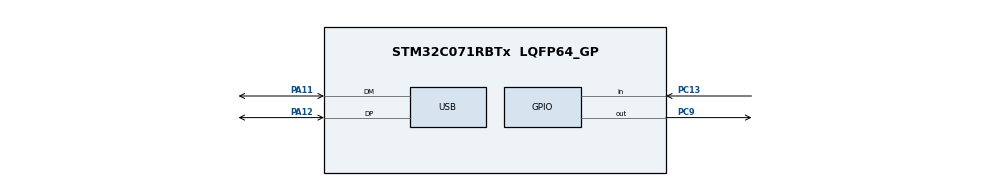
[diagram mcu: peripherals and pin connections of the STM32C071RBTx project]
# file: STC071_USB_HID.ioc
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Mcu.Family=STM32C0
Mcu.Name=STM32C071RBTx
Mcu.Package=LQFP64_GP
NUCLEO-C071RB.BUTTON=1
NUCLEO-C071RB.Bsp_Common_DEMO=true
NUCLEO-C071RB.LD1=true
NUCLEO-C071RB.LD2=true
NUCLEO-C071RB.VCP=true
NVIC.EXTI4_15_IRQn=true\:0\:0\:false\:false\:true\:false\:true\:true
NVIC.USB_DRD_FS_IRQn=true\:0\:0\:false\:false\:true\:true\:true\:true
PA11\ [PA9].Mode=Device
PA11\ [PA9].Signal=USB_DM
PA12\ [PA10].Mode=Device
PA12\ [PA10].Signal=USB_DP
PA13.Mode=Serial_Wire
PA13.Signal=DEBUG_SWDIO
PA14-BOOT0.Mode=Serial_Wire
PA14-BOOT0.Signal=DEBUG_SWCLK
PA2.Signal=USART2_TX
PA3.Signal=USART2_RX
PC13.Signal=GPIO_Input
PC9.Signal=GPIO_Output
PF0-OSC_IN(PF0).Mode=HSE-External-Oscillator
PF0-OSC_IN(PF0).Signal=RCC_OSC_IN
PF1-OSC_OUT(PF1).Mode=HSE-External-Oscillator
PF1-OSC_OUT(PF1).Signal=RCC_OSC_OUT
ProjectManager.HeapSize=0x1000
ProjectManager.StackSize=0x1000
ProjectManager.TargetToolchain=EWARM V9.30
RCC.ADCFreq_Value=48000000
RCC.AHBFreq_Value=48000000
RCC.CortexFreq_Value=48000000
RCC.EXTERNAL_CLOCK_VALUE=12288000
RCC.HCLKFreq_Value=48000000
RCC.HSE_VALUE=48000000
RCC.HSI48_VALUE=48000000
RCC.HSI_VALUE=48000000
RCC.LSE_VALUE=32768
RCC.SYSCLKFreq_VALUE=48000000
RCC.SYSCLKSource=RCC_SYSCLKSOURCE_HSE
USB.VirtualMode=Device_Only
USBX.BSP.number=1
USBX.Core_System=1
USBX.REG_USBX_DEVICE_CON_CK=0
USBX.USBD_COMPOSITE_USE_IAD=0
USBX.USBX_DEVICE_SYS_SIZE=5*1024
USBX.UX_DEVICE_APP_MEM_POOL_SIZE_STANDALONE=10*1024
USBX.UX_DEVICE_HID_CORE=1
USBX.UX_DEVICE_HID_MOUSE=1
USBX.UX_Device_Controller=1
USBX.UX_Device_CoreStack=1
USBX.UX_SLAVE_REQUEST_DATA_MAX_LENGTH=64
USBX0.BSP.STBoard=false
USBX0.BSP.api=Unknown
USBX0.BSP.instance=USB
USBX0.BSP.ip=USB
USBX0.BSP.mode=Device_Only
USBX0.BSP.name=USB_Device
USBX0.BSP.solution=USB
VP_NUCLEO-C071RB_VS_BSP_COMMON.Mode=COMMON
VP_USBX_Core_System.Mode=Core_System
VP_USBX_UX\ Device\ Controller_FS.Mode=UX_Device_Controller_FS
VP_USBX_UX\ Device\ CoreStack_FS.Mode=UX_Device_CoreStack_FS
VP_USBX_UX\ Device\ HID_CORE_FS.Mode=UX_Device_class_HID_CORE_FS
VP_USBX_UX\ Device\ HID_MOUSE_FS.Mode=UX_Device_class_HID_MOUSE_FS
board=NUCLEO-C071RB

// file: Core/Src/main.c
/* USER CODE BEGIN Header */
/**
  ******************************************************************************
  * @file           : main.c
  * @brief          : Main program body
  ******************************************************************************
  * @attention
  *
  * Copyright (c) 2026 STMicroelectronics.
  * All rights reserved.
  *
  * This software is licensed under terms that can be found in the LICENSE file
  * in the root directory of this software component.
  * If no LICENSE file comes with this software, it is provided AS-IS.
  *
  ******************************************************************************
  */
/* USER CODE END Header */
#include "main.h"
#include "usb.h"
#include "app_usbx_device.h"
#include "gpio.h"

COM_InitTypeDef BspCOMInit;
__IO uint32_t BspButtonState = BUTTON_RELEASED;

/* USER CODE BEGIN PV */

const char software_version[] = "V0.0.1";

/* USER CODE END PV */

void SystemClock_Config(void);

int main(void)
{

  /* MCU Configuration--------------------------------------------------------*/

  /* Reset of all peripherals, Initializes the Flash interface and the Systick. */
  HAL_Init();

  /* Configure the system clock */
  SystemClock_Config();

  /* Initialize all configured peripherals */
  MX_GPIO_Init();
  MX_USBX_Device_Init();

  /* Initialize leds */
  BSP_LED_Init(LED_GREEN);
  BSP_LED_Init(LED_BLUE);

  /* Initialize USER push-button, will be used to trigger an interrupt each time it's pressed.*/
  BSP_PB_Init(BUTTON_USER, BUTTON_MODE_EXTI);

  /* Initialize COM1 port (115200, 8 bits (7-bit data + 1 stop bit), no parity */
  BspCOMInit.BaudRate   = 115200;
  BspCOMInit.WordLength = COM_WORDLENGTH_8B;
  BspCOMInit.StopBits   = COM_STOPBITS_1;
  BspCOMInit.Parity     = COM_PARITY_NONE;
  BspCOMInit.HwFlowCtl  = COM_HWCONTROL_NONE;
  if (BSP_COM_Init(COM1, &BspCOMInit) != BSP_ERROR_NONE)
  {
    Error_Handler();
  }

  /* USER CODE BEGIN BSP */

  /* -- Sample board code to send message over COM1 port ---- */

  printf("%s\n\r", software_version);
  printf("USB HID MOUSE!\n\r");

  /* -- Sample board code to switch on leds ---- */
  BSP_LED_On(LED_GREEN);
  BSP_LED_On(LED_BLUE);

  /* USER CODE END BSP */

  /* Infinite loop */
  /* USER CODE BEGIN WHILE */
  while (1)
  {

    /* -- Sample board code for User push-button in interrupt mode ---- */
    if (BspButtonState == BUTTON_PRESSED)
    {
      /* Update button state */
      BspButtonState = BUTTON_RELEASED;
      /* -- Sample board code to toggle leds ---- */
      BSP_LED_Toggle(LED_GREEN);
      BSP_LED_Toggle(LED_BLUE);

      /* ..... Perform your action ..... */
    }
    /* USER CODE END WHILE */

    /* USER CODE BEGIN 3 */
    USBX_Device_Process(NULL);
  }
  /* USER CODE END 3 */
}

void SystemClock_Config(void)
{
  RCC_OscInitTypeDef RCC_OscInitStruct = {0};
  RCC_ClkInitTypeDef RCC_ClkInitStruct = {0};

  __HAL_FLASH_SET_LATENCY(FLASH_LATENCY_1);

  /** Initializes the RCC Oscillators according to the specified parameters
  * in the RCC_OscInitTypeDef structure.
  */
  RCC_OscInitStruct.OscillatorType = RCC_OSCILLATORTYPE_HSE|RCC_OSCILLATORTYPE_HSI48;
  RCC_OscInitStruct.HSEState = RCC_HSE_ON;
  RCC_OscInitStruct.HSI48State = RCC_HSI48_ON;

  if (HAL_RCC_OscConfig(&RCC_OscInitStruct) != HAL_OK)
  {
    Error_Handler();
  }

  /** Initializes the CPU, AHB and APB buses clocks
  */
  RCC_ClkInitStruct.ClockType = RCC_CLOCKTYPE_HCLK|RCC_CLOCKTYPE_SYSCLK
                              |RCC_CLOCKTYPE_PCLK1;
  RCC_ClkInitStruct.SYSCLKSource = RCC_SYSCLKSOURCE_HSE;
  RCC_ClkInitStruct.SYSCLKDivider = RCC_SYSCLK_DIV1;
  RCC_ClkInitStruct.AHBCLKDivider = RCC_HCLK_DIV1;
  RCC_ClkInitStruct.APB1CLKDivider = RCC_APB1_DIV1;

  if (HAL_RCC_ClockConfig(&RCC_ClkInitStruct, FLASH_LATENCY_1) != HAL_OK)
  {
    Error_Handler();
  }
}

/**
  * @brief  BSP Push Button callback
  * @param  Button Specifies the pressed button
  * @retval None
  */
void BSP_PB_Callback(Button_TypeDef Button)
{
  if (Button == BUTTON_USER)
  {
    BspButtonState = BUTTON_PRESSED;
  }
}

void Error_Handler(void)
{
  __disable_irq();
  while (1)
  {
  }
}
